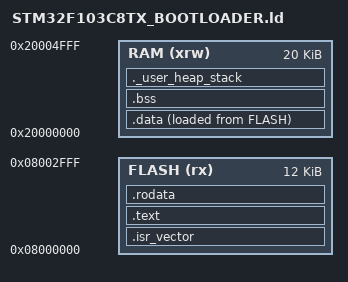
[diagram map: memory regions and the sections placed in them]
/*
 * STM32F103CBT6_BOOTLOADER.ld
 * Linker script for the BOOTLOADER project.
 * Bootloader occupies 0x08000000–0x08002FFF (12 KB).
 * Flash with ST-Link once and never again.
 */

ENTRY(Reset_Handler)

_estack = 0x20004FF8;  /* Reserve top 8 bytes (0x20004FF8-0x20004FFF) for SRAM flags */

_Min_Heap_Size  = 0x100;
_Min_Stack_Size = 0x400;

MEMORY
{
  FLASH (rx)  : ORIGIN = 0x08000000, LENGTH = 12K
  RAM   (xrw) : ORIGIN = 0x20000000, LENGTH = 20K
}

SECTIONS
{
  .isr_vector :
  {
    . = ALIGN(4);
    KEEP(*(.isr_vector))
    . = ALIGN(4);
  } >FLASH

  .text :
  {
    . = ALIGN(4);
    *(.text)
    *(.text*)
    *(.glue_7)
    *(.glue_7t)
    *(.eh_frame)
    KEEP(*(.init))
    KEEP(*(.fini))
    . = ALIGN(4);
    _etext = .;
  } >FLASH

  .rodata :
  {
    . = ALIGN(4);
    *(.rodata)
    *(.rodata*)
    . = ALIGN(4);
  } >FLASH

  _sidata = LOADADDR(.data);  /* used by startup to init .data */

  .data :
  {
    . = ALIGN(4);
    _sdata = .;
    *(.data)
    *(.data*)
    . = ALIGN(4);
    _edata = .;
  } >RAM AT> FLASH

  .bss :
  {
    . = ALIGN(4);
    _sbss = .;
    __bss_start__ = _sbss;
    *(.bss)
    *(.bss*)
    *(COMMON)
    . = ALIGN(4);
    _ebss = .;
    __bss_end__ = _ebss;
  } >RAM

  ._user_heap_stack :
  {
    . = ALIGN(8);
    PROVIDE ( end = . );
    PROVIDE ( _end = . );
    . = . + _Min_Heap_Size;
    . = . + _Min_Stack_Size;
    . = ALIGN(8);
  } >RAM

  /DISCARD/ :
  {
    libc.a ( * )
    libm.a ( * )
    libgcc.a ( * )
  }
}
